AUTOSAR XML (schema 4-2-2)
package /Test_Diag
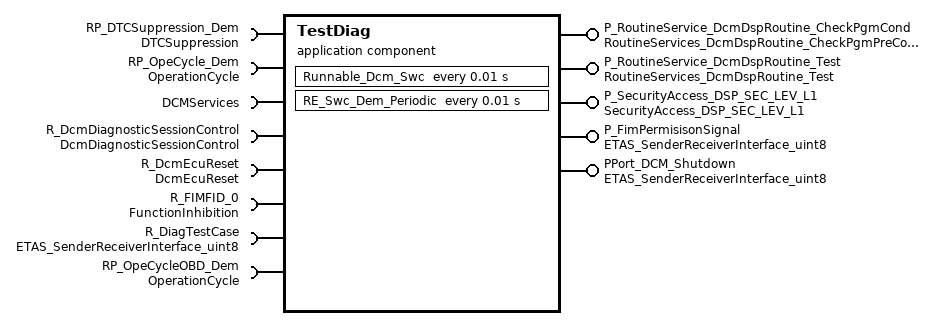
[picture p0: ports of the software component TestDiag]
  application sw component type TestDiag
    require port RP_DTCSuppression_Dem: required-interface=DTCSuppression
    require port RP_OpeCycle_Dem: required-interface=OperationCycle
    provide port P_RoutineService_DcmDspRoutine_CheckPgmCond: provided-com-specs=[Start, Stop, RequestResults], provided-interface=RoutineServices_DcmDspRoutine_CheckPgmPreCond
    provide port P_RoutineService_DcmDspRoutine_Test: provided-com-specs=[Start, Stop, RequestResults], provided-interface=RoutineServices_DcmDspRoutine_Test
    provide port P_SecurityAccess_DSP_SEC_LEV_L1: provided-com-specs=[{operation=CompareKey, queue-length=1}, {operation=GetSeed, queue-length=1}], provided-interface=SecurityAccess_DSP_SEC_LEV_L1
    4 x require port:
      DCMServices: required-interface=DCMServices
      R_DcmDiagnosticSessionControl: required-interface=DcmDiagnosticSessionControl
      R_DcmEcuReset: required-interface=DcmEcuReset
      R_FIMFID_0: required-interface=FunctionInhibition
    provide port P_FimPermisisonSignal: provided-interface=ETAS_SenderReceiverInterface_uint8
    require port R_DiagTestCase: required-interface=ETAS_SenderReceiverInterface_uint8
    provide port PPort_DCM_Shutdown: provided-interface=ETAS_SenderReceiverInterface_uint8
    require port RP_OpeCycleOBD_Dem: required-interface=OperationCycle
    behavior IB_TestDiG: data-type-mapping=[DTS_DcmDiagnosticSessionControl, DTS_DcmEcuReset, ComMModeMapping, DTS_MDG_ECUM_STATE]
      timing event TimingEvent_Dcm: start-on-event=Runnable_Dcm_Swc, period=0.01
      8 x operation invoked event:
        OIE_DSP_SEC_LEV_L1_GS: start-on-event=Swc_DSP_SEC_LEV_L1_GS, operation=P_SecurityAccess_DSP_SEC_LEV_L1.GetSeed
        OIE_DSP_SEC_LEV_L1_CK: start-on-event=Swc_DSP_SEC_LEV_L1_CK, operation=P_SecurityAccess_DSP_SEC_LEV_L1.CompareKey
        OIE_RoutineServices_DcmDspRoutine_Test_Start: start-on-event=Swc_RoutineServices_DcmDspRoutine_Test_Start, operation=P_RoutineService_DcmDspRoutine_Test.Start
        OIE_RoutineServices_DcmDspRoutine_Test_Stop: start-on-event=Swc_RoutineServices_DcmDspRoutine_Test_Stop, operation=P_RoutineService_DcmDspRoutine_Test.Stop
        OIE_RoutineServices_DcmDspRoutine_Test_Result: start-on-event=Swc_RoutineServices_DcmDspRoutine_Test_Result, operation=P_RoutineService_DcmDspRoutine_Test.RequestResults
        OIE_RoutineServices_DcmDspRoutine_CheckProgCond_Result: start-on-event=Swc_RoutineServices_DcmDspRoutine_CheckProgCond_Result, operation=P_RoutineService_DcmDspRoutine_CheckPgmCond.RequestResults
        OIE_RoutineServices_DcmDspRoutine_CheckProgCond_Start: start-on-event=Swc_RoutineServices_DcmDspRoutine_CheckProgCond_Start, operation=P_RoutineService_DcmDspRoutine_CheckPgmCond.Start
        OIE_RoutineServices_DcmDspRoutine_CheckProgCond_Stop: start-on-event=Swc_RoutineServices_DcmDspRoutine_CheckProgCond_Stop, operation=P_RoutineService_DcmDspRoutine_CheckPgmCond.Stop
      timing event TE_Swc_Dem_Periodic: start-on-event=RE_Swc_Dem_Periodic, period=0.01
      per instance memory NeTSWR_u_BoardID: base-type=uint32, type=NeTSWR_u_BoardID_UInt32, type-definition=UInt32
      11 x runnable:
        Runnable_Dcm_Swc: mode-access-points=[R_DcmDiagnosticSessionControl.MDGP_DcmDiagnosticSessionControl, R_DcmEcuReset.MDGP_DcmEcuReset], symbol=RunnableEntity_dcm
          data-receive-point-by-values:
            access DRPV_uint8_0: accessed-variable=R_DiagTestCase.uint8
          data-send-points:
            access DSP_uint8_0: accessed-variable=P_FimPermisisonSignal.uint8
            access DSP_uint8_1: accessed-variable=PPort_DCM_Shutdown.uint8
          4 x sync call:
            SSC_GetActiveProtocol: operation=DCMServices.GetActiveProtocol
            SSC_GetSecurityLevel: operation=DCMServices.GetSecurityLevel
            SSC_GetSesCtrlType: operation=DCMServices.GetSesCtrlType
            SSC_ResetToDefaultSession: operation=DCMServices.ResetToDefaultSession
        Swc_DSP_SEC_LEV_L1_CK: symbol=Swc_DSP_SEC_LEV_L1_CK_func
        Swc_DSP_SEC_LEV_L1_GS: symbol=Swc_DSP_SEC_LEV_L1_GS_func
        Swc_RoutineServices_DcmDspRoutine_Test_Start: symbol=Swc_RoutineServices_DcmDspRoutine_Test_Start_func
        Swc_RoutineServices_DcmDspRoutine_Test_Stop: symbol=Swc_RoutineServices_DcmDspRoutine_Test_Stop_func
        Swc_RoutineServices_DcmDspRoutine_Test_Result: symbol=Swc_RoutineServices_DcmDspRoutine_Test_Result_func
        Swc_RoutineServices_DcmDspRoutine_CheckProgCond_Result: symbol=Swc_RoutineServices_DcmDspRoutine_CheckProgCond_Result_func
        Swc_RoutineServices_DcmDspRoutine_CheckProgCond_Start: symbol=Swc_RoutineServices_DcmDspRoutine_CheckProgCond_Start_func
        Swc_RoutineServices_DcmDspRoutine_CheckProgCond_Stop: symbol=Swc_RoutineServices_DcmDspRoutine_CheckProgCond_Stop_func
        RE_Swc_Dem_Periodic
          sync call SynchronousServerCallPoint_00: operation=RP_DTCSuppression_Dem.SetDTCSuppression
          sync call SynchronousServerCallPoint_28: operation=RP_OpeCycle_Dem.SetOperationCycleState
          sync call SynchronousServerCallPoint_0: operation=RP_OpeCycleOBD_Dem.SetOperationCycleState
        RE_FiM_Swc: symbol=Swc_FiM_GetPermissionStatus
          sync call SynchronousServerCallPoint_FiMID_0: operation=R_FIMFID_0.GetFunctionPermission
      swc service dependency SwcNeTSWR_u_BoardID: assigned-datas=role-based-data-assignment={role=ramBlock, used-pim=NeTSWR_u_BoardID}
        service-needs:
          nv block needs SwcNeTSWR_u_BoardID: restore-at-start=true, store-at-shutdown=true
